# ATSAME53N19A device description
Architecture: CORTEX-M4; Family: SAME; Series: SAME53
Registers are 32-bit, read-write, reset 0x0 unless marked. A register's access mark holds for its fields unless they carry their own. Offsets are from the block's base; [hi:lo] are bit positions; lines under a group give offsets from that group; {n}, {i} and the like mark numbered series; 'fields as' and 'values as' point back to an identical list; <NAME> marks a mode.

## RTC — Real-Time Counter
Instances: RTC 0x40002400
Modes: MODE0 when RTC.MODE0.CTRLA.MODE=0 (32-bit Counter with Single 32-bit Compare); MODE1 when RTC.MODE1.CTRLA.MODE=1 (16-bit Counter with Two 16-bit Compares); MODE2 when RTC.MODE2.CTRLA.MODE=2 (Clock/Calendar with Alarm)
0x0E DBGCTRL 8-bit — Debug Control
  [0] DBGRUN — Run During Debug
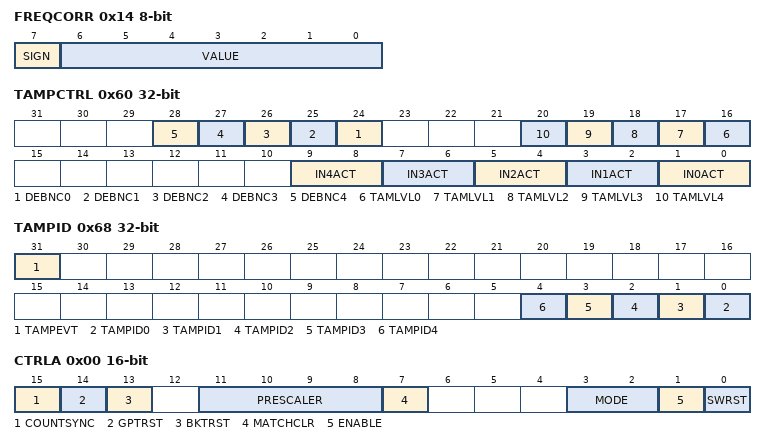
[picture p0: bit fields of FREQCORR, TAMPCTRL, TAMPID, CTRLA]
0x14 FREQCORR 8-bit (WSYNC) — Frequency Correction
  [7] SIGN — Correction Sign
  [6:0] VALUE — Correction Value
{0x40+4i} GP[{i}] (i=0..3) — General Purpose
0x60 TAMPCTRL — Tamper Control
  [n+24] DEBNC{n} (n=0..4) — Debouncer Enable {n}
  [n+16] TAMLVL{n} (n=0..4) — Tamper Level Select {n}
  [2n+1:2n] IN{n}ACT (n=0..4) — Tamper Input {n} Action
    0=OFF (Off (Disabled)); 1=WAKE (Wake without timestamp); 2=CAPTURE (Capture timestamp); 3=ACTL (Compare IN{n} to OUT)
0x68 TAMPID — Tamper ID
  [31] TAMPEVT — Tamper Event Detected
  [n] TAMPID{n} (n=0..4) — Tamper Input {n} Detected
{0x80+4i} BKUP[{i}] (i=0..7) — Backup
0x00 CTRLA <MODE0> 16-bit (WSYNC) — MODE0 Control A
  [15] COUNTSYNC — Count Read Synchronization Enable
  [14] GPTRST — GP Registers Reset On Tamper Enable
  [13] BKTRST — BKUP Registers Reset On Tamper Enable
  [11:8] PRESCALER
    0=OFF (CLK_RTC_CNT = GCLK_RTC/1); 1=DIV1 (CLK_RTC_CNT = GCLK_RTC/1); 2=DIV2 (CLK_RTC_CNT = GCLK_RTC/2); 3=DIV4 (CLK_RTC_CNT = GCLK_RTC/4); 4=DIV8 (CLK_RTC_CNT = GCLK_RTC/8); 5=DIV16 (CLK_RTC_CNT = GCLK_RTC/16); 6=DIV32 (CLK_RTC_CNT = GCLK_RTC/32); 7=DIV64 (CLK_RTC_CNT = GCLK_RTC/64); 8=DIV128 (CLK_RTC_CNT = GCLK_RTC/128); 9=DIV256 (CLK_RTC_CNT = GCLK_RTC/256); 10=DIV512 (CLK_RTC_CNT = GCLK_RTC/512); 11=DIV1024 (CLK_RTC_CNT = GCLK_RTC/1024)
  [7] MATCHCLR — Clear on Match
  [3:2] MODE — Operating Mode
    0=COUNT32 (Mode 0: 32-bit Counter); 1=COUNT16 (Mode 1: 16-bit Counter); 2=CLOCK (Mode 2: Clock/Calendar)
  [1] ENABLE
  [0] SWRST — Software Reset
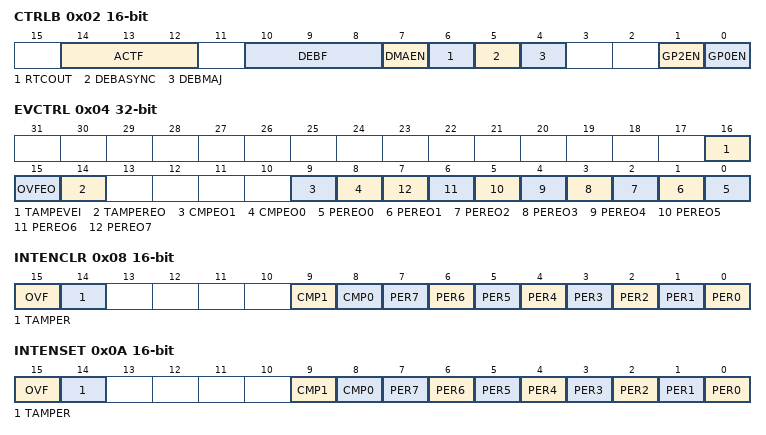
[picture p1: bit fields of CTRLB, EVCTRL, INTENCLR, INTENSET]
0x02 CTRLB <MODE0> 16-bit — MODE0 Control B
  [14:12] ACTF — Active Layer Freqnuency
    0=DIV2 (CLK_RTC_OUT = CLK_RTC/2); 1=DIV4 (CLK_RTC_OUT = CLK_RTC/4); 2=DIV8 (CLK_RTC_OUT = CLK_RTC/8); 3=DIV16 (CLK_RTC_OUT = CLK_RTC/16); 4=DIV32 (CLK_RTC_OUT = CLK_RTC/32); 5=DIV64 (CLK_RTC_OUT = CLK_RTC/64); 6=DIV128 (CLK_RTC_OUT = CLK_RTC/128); 7=DIV256 (CLK_RTC_OUT = CLK_RTC/256)
  [10:8] DEBF — Debounce Freqnuency
    0=DIV2 (CLK_RTC_DEB = CLK_RTC/2); 1=DIV4 (CLK_RTC_DEB = CLK_RTC/4); 2=DIV8 (CLK_RTC_DEB = CLK_RTC/8); 3=DIV16 (CLK_RTC_DEB = CLK_RTC/16); 4=DIV32 (CLK_RTC_DEB = CLK_RTC/32); 5=DIV64 (CLK_RTC_DEB = CLK_RTC/64); 6=DIV128 (CLK_RTC_DEB = CLK_RTC/128); 7=DIV256 (CLK_RTC_DEB = CLK_RTC/256)
  [7] DMAEN — DMA Enable
  [6] RTCOUT — RTC Output Enable
  [5] DEBASYNC — Debouncer Asynchronous Enable
  [4] DEBMAJ — Debouncer Majority Enable
  [1] GP2EN — General Purpose 2 Enable
  [0] GP0EN — General Purpose 0 Enable
0x04 EVCTRL <MODE0> — MODE0 Event Control
  [16] TAMPEVEI — Tamper Event Input Enable
  [15] OVFEO — Overflow Event Output Enable
  [14] TAMPEREO — Tamper Event Output Enable
  [9] CMPEO1 — Compare 1 Event Output Enable
  [8] CMPEO0 — Compare 0 Event Output Enable
  [n] PEREO{n} (n=0..7) — Periodic Interval {n} Event Output Enable
0x08 INTENCLR <MODE0> 16-bit (atomic clear) — MODE0 Interrupt Enable Clear
  [15] OVF — Overflow Interrupt Enable
  [14] TAMPER — Tamper Enable
  [9] CMP1 — Compare 1 Interrupt Enable
  [8] CMP0 — Compare 0 Interrupt Enable
  [n] PER{n} (n=0..7) — Periodic Interval {n} Interrupt Enable
0x0A INTENSET <MODE0> 16-bit (atomic set) — MODE0 Interrupt Enable Set
  fields as INTENCLR<MODE0>
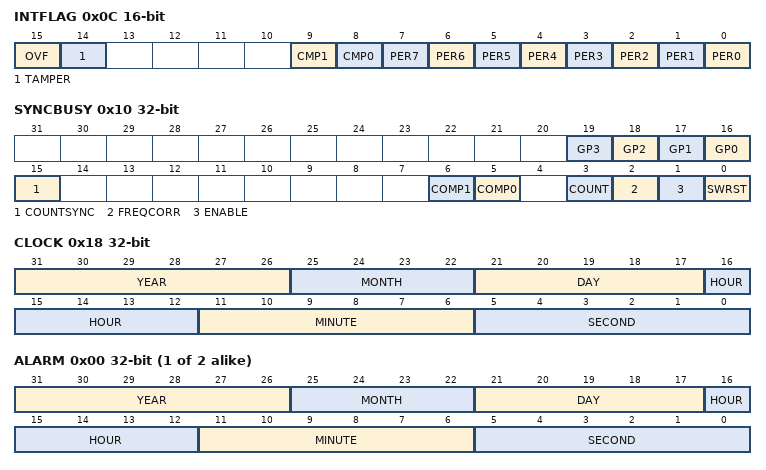
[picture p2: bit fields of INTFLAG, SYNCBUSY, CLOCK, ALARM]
0x0C INTFLAG <MODE0> 16-bit (atomic clear) — MODE0 Interrupt Flag Status and Clear
  [15] OVF — Overflow
  [14] TAMPER
  [9] CMP1 — Compare 1
  [8] CMP0 — Compare 0
  [n] PER{n} (n=0..7) — Periodic Interval {n}
0x10 SYNCBUSY <MODE0> ro — MODE0 Synchronization Busy Status
  [n+16] GP{n} (n=0..3) — General Purpose {n} Register Busy
  [15] COUNTSYNC — Count Synchronization Enable Bit Busy
  [6] COMP1 — COMP 1 Register Busy
  [5] COMP0 — COMP 0 Register Busy
  [3] COUNT — COUNT Register Busy
  [2] FREQCORR — FREQCORR Register Busy
  [1] ENABLE — Enable Bit Busy
  [0] SWRST — Software Reset Busy
0x18 COUNT <MODE0> (RSYNC) — MODE0 Counter Value
  [31:0] COUNT — Counter Value
{0x20+4i} COMP[{i}] (i=0..1) <MODE0> (WSYNC) — MODE0 Compare n Value
  [31:0] COMP — Compare Value
0x64 TIMESTAMP <MODE0> ro (RSYNC) — MODE0 Timestamp
  [31:0] COUNT — Count Timestamp Value
0x00 CTRLA <MODE1> 16-bit (WSYNC) — MODE1 Control A
  [15] COUNTSYNC — Count Read Synchronization Enable
  [14] GPTRST — GP Registers Reset On Tamper Enable
  [13] BKTRST — BKUP Registers Reset On Tamper Enable
  [11:8] PRESCALER
    values as CTRLA<MODE0>.PRESCALER
  [3:2] MODE — Operating Mode
    values as CTRLA<MODE0>.MODE
  [1] ENABLE
  [0] SWRST — Software Reset
0x02 CTRLB <MODE1> 16-bit — MODE1 Control B
  fields as CTRLB<MODE0>
0x04 EVCTRL <MODE1> — MODE1 Event Control
  [16] TAMPEVEI — Tamper Event Input Enable
  [15] OVFEO — Overflow Event Output Enable
  [14] TAMPEREO — Tamper Event Output Enable
  [n+8] CMPEO{n} (n=0..3) — Compare {n} Event Output Enable
  [n] PEREO{n} (n=0..7) — Periodic Interval {n} Event Output Enable
0x08 INTENCLR <MODE1> 16-bit (atomic clear) — MODE1 Interrupt Enable Clear
  [15] OVF — Overflow Interrupt Enable
  [14] TAMPER — Tamper Enable
  [n+8] CMP{n} (n=0..3) — Compare {n} Interrupt Enable
  [n] PER{n} (n=0..7) — Periodic Interval {n} Interrupt Enable
0x0A INTENSET <MODE1> 16-bit (atomic set) — MODE1 Interrupt Enable Set
  fields as INTENCLR<MODE1>
0x0C INTFLAG <MODE1> 16-bit (atomic clear) — MODE1 Interrupt Flag Status and Clear
  [15] OVF — Overflow
  [14] TAMPER
  [n+8] CMP{n} (n=0..3) — Compare {n}
  [n] PER{n} (n=0..7) — Periodic Interval {n}
0x10 SYNCBUSY <MODE1> ro — MODE1 Synchronization Busy Status
  [n+16] GP{n} (n=0..3) — General Purpose {n} Register Busy
  [15] COUNTSYNC — Count Synchronization Enable Bit Busy
  [n+5] COMP{n} (n=0..3) — COMP {n} Register Busy
  [4] PER — PER Register Busy
  [3] COUNT — COUNT Register Busy
  [2] FREQCORR — FREQCORR Register Busy
  [1] ENABLE — Enable Bit Busy
  [0] SWRST — Software Reset Bit Busy
0x18 COUNT <MODE1> 16-bit (RSYNC) — MODE1 Counter Value
  [15:0] COUNT — Counter Value
0x1C PER <MODE1> 16-bit (WSYNC) — MODE1 Counter Period
  [15:0] PER — Counter Period
{0x20+2i} COMP[{i}] (i=0..3) <MODE1> 16-bit (WSYNC) — MODE1 Compare n Value
  [15:0] COMP — Compare Value
0x64 TIMESTAMP <MODE1> ro (RSYNC) — MODE1 Timestamp
  [15:0] COUNT — Count Timestamp Value
0x00 CTRLA <MODE2> 16-bit (WSYNC) — MODE2 Control A
  [15] CLOCKSYNC — Clock Read Synchronization Enable
  [14] GPTRST — GP Registers Reset On Tamper Enable
  [13] BKTRST — BKUP Registers Reset On Tamper Enable
  [11:8] PRESCALER
    values as CTRLA<MODE0>.PRESCALER
  [7] MATCHCLR — Clear on Match
  [6] CLKREP — Clock Representation
  [3:2] MODE — Operating Mode
    values as CTRLA<MODE0>.MODE
  [1] ENABLE
  [0] SWRST — Software Reset
0x02 CTRLB <MODE2> 16-bit — MODE2 Control B
  fields as CTRLB<MODE0>
0x04 EVCTRL <MODE2> — MODE2 Event Control
  [16] TAMPEVEI — Tamper Event Input Enable
  [15] OVFEO — Overflow Event Output Enable
  [14] TAMPEREO — Tamper Event Output Enable
  [9] ALARMEO1 — Alarm 1 Event Output Enable
  [8] ALARMEO0 — Alarm 0 Event Output Enable
  [n] PEREO{n} (n=0..7) — Periodic Interval {n} Event Output Enable
0x08 INTENCLR <MODE2> 16-bit (atomic clear) — MODE2 Interrupt Enable Clear
  [15] OVF — Overflow Interrupt Enable
  [14] TAMPER — Tamper Enable
  [9] ALARM1 — Alarm 1 Interrupt Enable
  [8] ALARM0 — Alarm 0 Interrupt Enable
  [n] PER{n} (n=0..7) — Periodic Interval {n} Interrupt Enable
0x0A INTENSET <MODE2> 16-bit (atomic set) — MODE2 Interrupt Enable Set
  [15] OVF — Overflow Interrupt Enable
  [14] TAMPER — Tamper Enable
  [9] ALARM1 — Alarm 1 Interrupt Enable
  [8] ALARM0 — Alarm 0 Interrupt Enable
  [n] PER{n} (n=0..7) — Periodic Interval {n} Enable
0x0C INTFLAG <MODE2> 16-bit (atomic clear) — MODE2 Interrupt Flag Status and Clear
  [15] OVF — Overflow
  [14] TAMPER
  [9] ALARM1
  [8] ALARM0
  [n] PER{n} (n=0..7) — Periodic Interval {n}
0x10 SYNCBUSY <MODE2> ro — MODE2 Synchronization Busy Status
  [n+16] GP{n} (n=0..3) — General Purpose {n} Register Busy
  [15] CLOCKSYNC — Clock Synchronization Enable Bit Busy
  [12] MASK1 — MASK 1 Register Busy
  [11] MASK0 — MASK 0 Register Busy
  [6] ALARM1 — ALARM 1 Register Busy
  [5] ALARM0 — ALARM 0 Register Busy
  [3] CLOCK — CLOCK Register Busy
  [2] FREQCORR — FREQCORR Register Busy
  [1] ENABLE — Enable Bit Busy
  [0] SWRST — Software Reset Bit Busy
0x18 CLOCK <MODE2> (RSYNC) — MODE2 Clock Value
  [31:26] YEAR
  [25:22] MONTH
  [21:17] DAY
  [16:12] HOUR
    0=AM (AM when CLKREP in 12-hour); 16=PM (PM when CLKREP in 12-hour)
  [11:6] MINUTE
  [5:0] SECOND
{0x20+8i} MODE2_ALARM[{i}] (i=0..1) <MODE2> group
  0x00 ALARM <MODE2> (WSYNC) — MODE2_ALARM Alarm n Value
    [31:26] YEAR
    [25:22] MONTH
    [21:17] DAY
    [16:12] HOUR
      0=AM (Morning hour); 16=PM (Afternoon hour)
    [11:6] MINUTE
    [5:0] SECOND
  0x04 MASK <MODE2> 8-bit (WSYNC) — MODE2_ALARM Alarm n Mask
    [2:0] SEL — Alarm Mask Selection
      0=OFF (Alarm Disabled); 1=SS (Match seconds only); 2=MMSS (Match seconds and minutes only); 3=HHMMSS (Match seconds, minutes, and hours only); 4=DDHHMMSS (Match seconds, minutes, hours, and days only); 5=MMDDHHMMSS (Match seconds, minutes, hours, days, and months only); 6=YYMMDDHHMMSS (Match seconds, minutes, hours, days, months, and years)
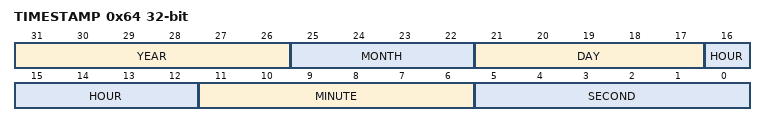
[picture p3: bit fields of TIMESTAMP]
0x64 TIMESTAMP <MODE2> ro (RSYNC) — MODE2 Timestamp
  [31:26] YEAR — Year Timestamp Value
  [25:22] MONTH — Month Timestamp Value
  [21:17] DAY — Day Timestamp Value
  [16:12] HOUR — Hour Timestamp Value
    values as CLOCK<MODE2>.HOUR
  [11:6] MINUTE — Minute Timestamp Value
  [5:0] SECOND — Second Timestamp Value
Value list RTC_TAMPCTRL__IN5ACT: 0=OFF (Off (Disabled)); 1=WAKE (Wake without timestamp); 2=CAPTURE (Capture timestamp); 3=ACTL (Compare IN5 to OUT)
Value list RTC_TAMPCTRL__IN6ACT: 0=OFF (Off (Disabled)); 1=WAKE (Wake without timestamp); 2=CAPTURE (Capture timestamp); 3=ACTL (Compare IN6 to OUT)
Value list RTC_TAMPCTRL__IN7ACT: 0=OFF (Off (Disabled)); 1=WAKE (Wake without timestamp); 2=CAPTURE (Capture timestamp); 3=ACTL (Compare IN7 to OUT)

## Notices in the file
Copyright (c) 2018 Microchip Technology Inc.
SPDX-License-Identifier: Apache-2.0
Licensed under the Apache License, Version 2.0 (the "License");
you may not use this file except in compliance with the License.
You may obtain a copy of the License at
http://www.apache.org/licenses/LICENSE-2.0
Unless required by applicable law or agreed to in writing, software
distributed under the License is distributed on an "AS IS" BASIS,
WITHOUT WARRANTIES OR CONDITIONS OF ANY KIND, either express or implied.
See the License for the specific language governing permissions and
limitations under the License.
